# PRU_ICSSG0_PR1_ICSS_ECAP0_ECAP_SLV_local register map
Vendor: Texas Instruments
Peripheral module from a debugger description file (folder PG1_0).
Registers are 32-bit, read-write, reset 0x0 unless marked. A register's access mark holds for its fields unless they carry their own. Offsets are as the file gives them; lines under a group give offsets from that group; [hi:lo] are bit positions; {n}, {i} and the like mark numbered series; 'fields as' and 'values as' point back to an identical list; <NAME> marks a mode.

## PRU_ICSSG0_PR1_ICSS_ECAP0_ECAP_SLV
0x00 ICSSG_TSCNT — Time Stamp Counter Register
  [31:0] TSCNT — Active 32-bit counter register which is used as the capture time-base .
0x04 ICSSG_CNTPHS — Counter Phase Control Register
  [31:0] CNTPHS — Counter phase value register that can be programmed for phase lag/lead. This register shadows
0x08 ICSSG_CAP1 — Capture-1 Register
  [31:0] CAP1 — This register can be loaded (written) by the following:a) Time-stamp (that is, counter value) during a capture event.(b) Software may be useful for test purposes/initialisation.(c) APRD shadow register (that is,
0x0C ICSSG_CAP2 — Capture-2 Register
  [31:0] CAP2 — This register can be loaded (written) by the following:a) Time-stamp (that is, counter value) during a capture event.b) Software may be useful for test purposes.c) ACMP shadow register (that is,
0x10 ICSSG_CAP3 — Capture-3 Register
  [31:0] CAP3 — In CMP mode this is a time-stamp capture register. In APWM mode this is the period shadow (APER) register. User updates the PWM period value via this register. In this mode
0x14 ICSSG_CAP4 — Capture-4 Register
  [31:0] CAP4 — In CMP mode this is a time-stamp capture register. In APWM mode this is the compare shadow (ACMP) register. User updates the PWM compare value via this register. In this mode
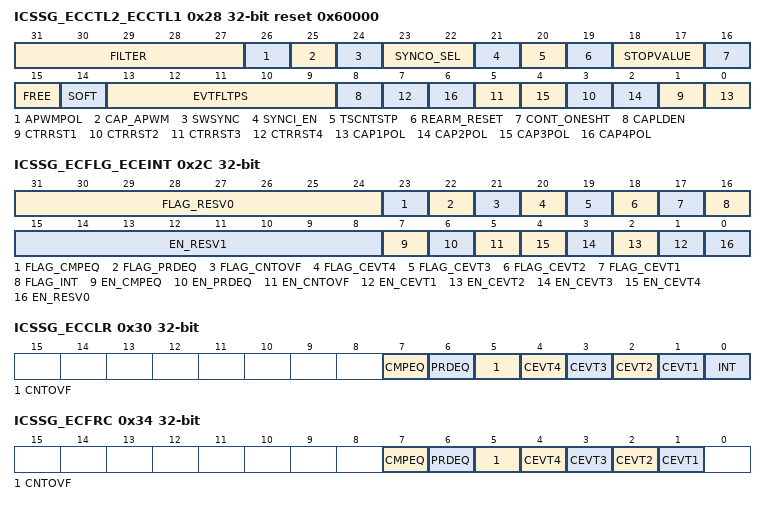
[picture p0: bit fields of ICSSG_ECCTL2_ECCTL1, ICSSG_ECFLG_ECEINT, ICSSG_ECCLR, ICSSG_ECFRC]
0x28 ICSSG_ECCTL2_ECCTL1 access per field reset 0x60000 — ECAP Control Register 1
  [31:27] FILTER ro
  [26] APWMPOL rw — APWM output polarity select:0 = output is active high (that is, compare value defines high time)1 = output is active low (that is, compare value defines low time)Note: This is applicable only in APWM operating mode.
  [25] CAP_APWM rw — CAP/APWM operating mode select:0 = ECAP module operates in capture mode. This mode forces the following configuration:a) Inhibitsb) Inhibits shadow loads onc) Permits user to enable ICSSG_CAP1 to ICSSG_CAP4 register load.d) ECAP input/APWM output pin operates as a capture input.1 = ECAP module operates in APWM mode. This mode forces the following configuration:a) Resets TSCNT on CTR = PRD event (period boundary).b) Permits shadow loading on ICSSG_CAP1 and ICSSG_CAP2 registers.c) Disables loading of time-stamps into ICSSG_CAP1 to ICSSG_CAP4 registers.d) ECAP input/APWM ouput pin operates as a APWM output.
  [24] SWSYNC rw — Software forced counter (0 = writing a zero has no effect will always return a zero1 = writing a one will force aNote: This provides a convenient software method to synchronize some or all ECAP timebases. In APWM mode, the synchronizing can also be done via the CTR = PRD event.
  [23:22] SYNCO_SEL rw — Sync-out select:0b00 = select sync-in event to be the sync-out signal (pass through)0b01 = select CTR = PRD event to be the sync-out signal0b10 = disable sync out signal0b11 = disable sync out signalNote: Selection CTR = PRD is meaningful only in APWM mode, however can still be chosen in CAP mode, if user believes it to be useful.
  [21] SYNCI_EN rw — Counter (0 = disable sync-in option1 = enable counter (
  [20] TSCNTSTP rw — Counter stop (freeze) control:0 = counter stopped1 = counter free running
  [19] REARM_RESET rw — One-shot re-arming, that is, wait for stop trigger:0 = writing a zero has no effect (reading always returns a 0)1 = writing a one arms the one-shot sequence as follows:1) resets the mod4 counter to zero2) un-freezes the mod4 counter3) enables capture register loadsNote: The re-arm function is valid in onesht or continous mode.
  [18:17] STOPVALUE rw — Stop value for one-shot mode. This is the number (between 1-4) of captures allowed to occur before the CAP(1-4) registers are frozen, that is, capture sequence is stopped.0b00 = stop after capture event 10b01 = stop after capture event 20b10 = stop after capture event 30b11 = stop after capture event 4Note: STOPVALUE is compared to mod4 counter, and when equal, the following two actions occur: (1) Mod4 counter is stopped (frozen). (2) Capture register loads are inhibited.Note: In one shot mode, further interrupt events are blocked until re-armed, once the number of events captured has been reached .
  [16] CONT_ONESHT rw — Continuous or one-shot mode control (applicable only in capture mode):0 = operate in continuous mode1 = operate in one-shot mode
  [15] FREE rw — Emulation control.0b00 =0b01 =0b1x =
  [14] SOFT rw — Emulation control.0b00 =0b01 =0b1x =
  [13:9] EVTFLTPS rw — Event filter prescale select:0b00000 divide by 1 (that is, no prescale, by-pass the prescaler)0b00001 divide by 20b00010 divide by 40b00011 divide by 60b00100 divide by 80b00101 divide by 100b11110 divide by 600b11111 divide by 62
  [8] CAPLDEN rw — Enable loading of CAP(1-4) registers on a capture event:0 = disable CAP 1-4 register loads at capture event time1 = enable CAP(1-4) register loads at capture event time
  [2n-1] CTRRST{n} rw (n=1..4) — Counter reset on capture event {n}:0 = do not reset counter on capture event {n} (absolute time stamp)1 = reset counter after event {n} time-stamp has been captured (used in difference mode operation)
  [2n-2] CAP{n}POL rw (n=1..4) — Capture event {n} polarity select:0 = capture event {n} triggered on a rising edge (RE)1 = capture event {n} triggered on a falling edge (FE)
0x2C ICSSG_ECFLG_ECEINT access per field — ECAP Interrupt Enable Register
  [31:24] FLAG_RESV0 ro
  [23] FLAG_CMPEQ ro — Compare equal status flag:0 = indicates no event occurred1 = indicates the counter (Note: This flag is only active in APWM mode.
  [22] FLAG_PRDEQ ro — Period equal status flag:0 = indicates no event occurred1 = indicates the counter (Note: This flag is only active in APWM mode.
  [21] FLAG_CNTOVF ro — Counter overflow status flag:0 = indicates no event occurred1 = indicates the counter (Note: This flag is active in CAP and APWM mode.
  [20] FLAG_CEVT4 ro — Capture event 4 status flag:0 = indicates no event occurred1 = indicates the fourth event occurred at ECAPx pinNote: This flag is only active in CAP mode.
  [19] FLAG_CEVT3 ro — Capture event 3 status flag:0 = indicates no event occurred1 = indicates the third event occurred at ECAPx pinNote: This flag is only active in CAP mode.
  [18] FLAG_CEVT2 ro — Capture event 2 status flag:0 = indicates no event occurred1 = indicates the second event occurred at ECAPx pinNote: This flag is only active in CAP mode.
  [17] FLAG_CEVT1 ro — Capture event 1 status flag:0 = indicates no event occurred1 = indicates the first event occurred at ECAPx pinNote: This flag is only active in CAP mode.
  [16] FLAG_INT ro — Global interrupt status flag:0 = indicates no interrupt generated1 = indicates that an interrupt was generated from one of the following events
  [15:8] EN_RESV1 ro
  [7] EN_CMPEQ rw — Compare equal interrupt enable:0 = disable compare equal as an interrupt source1 = enable compare equal as an interrupt source
  [6] EN_PRDEQ rw — Period equal interrupt enable:0 = disable period equal as an interrupt source1 = enable period equal as an interrupt source
  [5] EN_CNTOVF rw — Counter overflow interrupt enable:0 = disable counter overflow as an interrupt source1 = enable counter overflow as an interrupt source
  [n] EN_CEVT{n} rw (n=1..4) — Capture event {n} interrupt enable:0 = disable capture event 1 as an interrupt source1 = enable capture event 1 as an interrupt source
  [0] EN_RESV0 ro
0x30 ICSSG_ECCLR access per field — ECAP Interrupt Clear Register
  [7] CMPEQ rw — Compare equal status flag:0 = Writing a 0 has no effect. Always reads back a 0.1 = Writing a 1 clears the status flag condition
  [6] PRDEQ rw — Period equal status flag:0 = Writing a 0 has no effect. Always reads back a 0.1 = Writing a 1 clears the status flag condition
  [5] CNTOVF rw — Counter overflow status flag:0 = Writing a 0 has no effect. Always reads back a 0.1 = Writing a 1 clears the status flag condition
  [n] CEVT{n} rw (n=1..4) — Capture event {n} status flag:0 = Writing a 0 has no effect. Always reads back a 0.1 = Writing a 1 clears the status flag condition
  [0] INT rw — Global interrupt clear flag:0 = Writing a 0 has no effect. Always reads back a 0.1 = Writing a 1 clears the clear flag and enable further interrupts to be generated if any of the clear flags are set to 1
0x34 ICSSG_ECFRC access per field — ECAP Interrupt Forcing Register
  [7] CMPEQ rw — Force compare equal:0 = Writing of 0 is ignored. Always reads back a 0.1 = Writing a 1 sets the the CMPEQ flag bit
  [6] PRDEQ rw — Force period equal:0 = Writing of 0 is ignored. Always reads back a 0.1 = Writing a 1 sets the the PRDEQ flag bit
  [5] CNTOVF rw — Force counter overflow:0 = Writing of 0 is ignored. Always reads back a 0.1 = Writing a 1 sets the the CNTOVF flag bit
  [n] CEVT{n} rw (n=1..4) — Force capture event {n}:0 = Writing of 0 is ignored. Always reads back a 0.1 = Writing a 1 sets the the CEVT{n} flag bit
0x5C ICSSG_PID ro reset 0x44D22100 — ECAP Peripheral Id Register
  [31:0] REVID — TI internal data.
